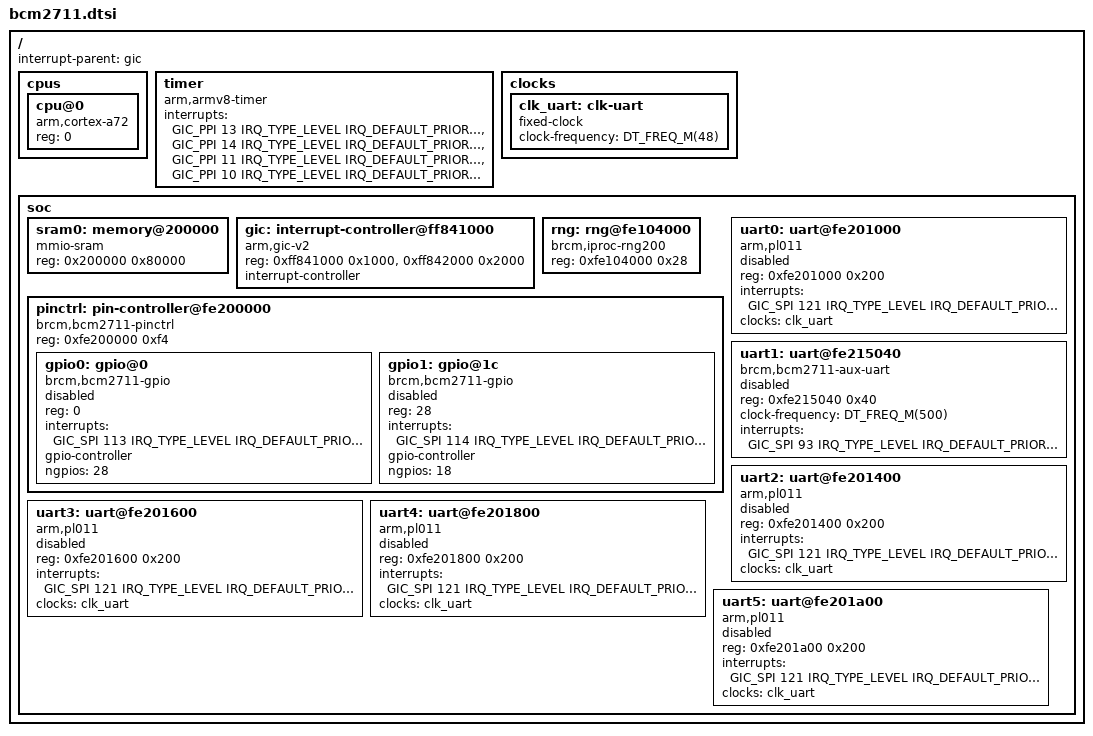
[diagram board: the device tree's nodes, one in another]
/*
 * Copyright 2023 honglin leng <a909204013@gmail.com>
 * Copyright (c) 2025 Muhammad Waleed Badar
 *
 * SPDX-License-Identifier: Apache-2.0
 */

#include <mem.h>
#include <freq.h>

#include <arm64/armv8-a.dtsi>
#include <zephyr/dt-bindings/interrupt-controller/arm-gic.h>

/ {
	cpus {
		#address-cells = <1>;
		#size-cells = <0>;

		cpu@0 {
			device_type = "cpu";
			compatible = "arm,cortex-a72";
			reg = <0>;
		};
	};

	interrupt-parent = <&gic>;

	timer {
		compatible = "arm,armv8-timer";
		interrupts = <GIC_PPI 13 IRQ_TYPE_LEVEL
			      IRQ_DEFAULT_PRIORITY>,
			     <GIC_PPI 14 IRQ_TYPE_LEVEL
			      IRQ_DEFAULT_PRIORITY>,
			     <GIC_PPI 11 IRQ_TYPE_LEVEL
			      IRQ_DEFAULT_PRIORITY>,
			     <GIC_PPI 10 IRQ_TYPE_LEVEL
			      IRQ_DEFAULT_PRIORITY>;
	};

	clocks {
		clk_uart: clk-uart {
			compatible = "fixed-clock";
			clock-frequency = <DT_FREQ_M(48)>;
			#clock-cells = <0>;
		};
	};

	soc {
		sram0: memory@200000 {
			device_type = "memory";
			compatible = "mmio-sram";
			reg = <0x200000 0x80000>;
		};

		gic: interrupt-controller@ff841000 {
			compatible = "arm,gic-v2", "arm,gic";
			reg = <0xff841000 0x1000>,
			      <0xff842000 0x2000>;
			interrupt-controller;
			#interrupt-cells = <4>;
			status = "okay";
		};

		rng: rng@fe104000 {
			compatible = "brcm,iproc-rng200";
			reg = <0xfe104000 0x28>;
			status = "okay";
		};

		pinctrl: pin-controller@fe200000 {
			compatible = "brcm,bcm2711-pinctrl";
			reg = <0xfe200000 0xf4>;
			#address-cells = <1>;
			#size-cells = <0>;

			/* GPIO 0 ~ 27 */
			gpio0: gpio@0 {
				compatible = "brcm,bcm2711-gpio";
				reg = <0>;
				interrupts = <GIC_SPI 113 IRQ_TYPE_LEVEL
					      IRQ_DEFAULT_PRIORITY>;
				gpio-controller;
				#gpio-cells = <2>;
				ngpios = <28>;
				status = "disabled";
			};

			/* GPIO 28 ~ 45 */
			gpio1: gpio@1c {
				compatible = "brcm,bcm2711-gpio";
				reg = <28>;
				interrupts = <GIC_SPI 114 IRQ_TYPE_LEVEL
					      IRQ_DEFAULT_PRIORITY>;
				gpio-controller;
				#gpio-cells = <2>;
				ngpios = <18>;
				status = "disabled";
			};
		};

		uart0: uart@fe201000 {
			compatible = "arm,pl011";
			reg = <0xfe201000 0x200>;
			interrupts = <GIC_SPI 121 IRQ_TYPE_LEVEL
				      IRQ_DEFAULT_PRIORITY>;
			interrupt-names = "uart0";
			clocks = <&clk_uart>;
			status = "disabled";
		};

		uart1: uart@fe215040 {
			compatible = "brcm,bcm2711-aux-uart";
			reg = <0xfe215040 0x40>;
			clock-frequency = <DT_FREQ_M(500)>;
			interrupts = <GIC_SPI 93 IRQ_TYPE_LEVEL
				      IRQ_DEFAULT_PRIORITY>;
			status = "disabled";
		};

		uart2: uart@fe201400 {
			compatible = "arm,pl011";
			reg = <0xfe201400 0x200>;
			interrupts = <GIC_SPI 121 IRQ_TYPE_LEVEL
				      IRQ_DEFAULT_PRIORITY>;
			interrupt-names = "uart2";
			clocks = <&clk_uart>;
			status = "disabled";
		};

		uart3: uart@fe201600 {
			compatible = "arm,pl011";
			reg = <0xfe201600 0x200>;
			interrupts = <GIC_SPI 121 IRQ_TYPE_LEVEL
				      IRQ_DEFAULT_PRIORITY>;
			interrupt-names = "uart3";
			clocks = <&clk_uart>;
			status = "disabled";
		};

		uart4: uart@fe201800 {
			compatible = "arm,pl011";
			reg = <0xfe201800 0x200>;
			interrupts = <GIC_SPI 121 IRQ_TYPE_LEVEL
				      IRQ_DEFAULT_PRIORITY>;
			interrupt-names = "uart4";
			clocks = <&clk_uart>;
			status = "disabled";
		};

		uart5: uart@fe201a00 {
			compatible = "arm,pl011";
			reg = <0xfe201a00 0x200>;
			interrupts = <GIC_SPI 121 IRQ_TYPE_LEVEL
				      IRQ_DEFAULT_PRIORITY>;
			interrupt-names = "uart5";
			clocks = <&clk_uart>;
			status = "disabled";
		};
	};
};
